# SN32F240B register map
Vendor: SONiX Technology Co., Ltd.; Series: SN32F240B; File version: 1.1
CPU: CM0 r0p0, little endian, no MPU, no FPU, 2 interrupt priority bits
Registers are 32-bit, read-write, reset 0x0 unless marked. A register's access mark holds for its fields unless they carry their own. Offsets are from the block's base; [hi:lo] are bit positions; {n}, {i} and the like mark numbered series.

## SN_SYS1 — System Control Registers
Base 0x4005E000
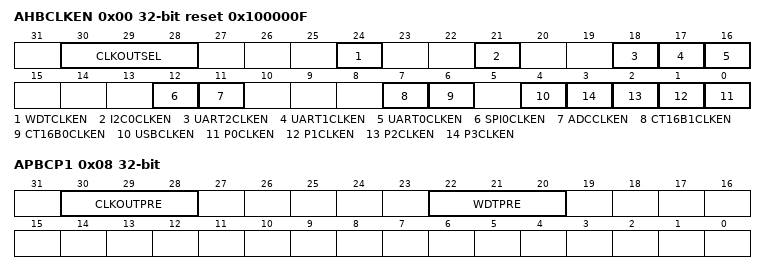
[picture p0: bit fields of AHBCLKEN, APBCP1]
0x00 AHBCLKEN reset 0x100000F — Offset:0x00 AHB Clock Enable Register
  [30:28] CLKOUTSEL — Clock output source selection
    0=Disable; 1=ILRC; 4=HCLK; 5=IHRC
  [24] WDTCLKEN — Enable AHB clock for WDT
    0=Disable; 1=Enable
  [21] I2C0CLKEN — Enable AHB clock for I2C0
    0=Disable; 1=Enable
  [18] UART2CLKEN — Enable AHB clock for UART2
    0=Disable; 1=Enable
  [17] UART1CLKEN — Enable AHB clock for UART1
    0=Disable; 1=Enable
  [16] UART0CLKEN — Enable AHB clock for UART0
    0=Disable; 1=Enable
  [12] SPI0CLKEN — Enable AHB clock for SPI0
    0=Disable; 1=Enable
  [11] ADCCLKEN — Enable AHB clock for ADC
    0=Disable; 1=Enable
  [7] CT16B1CLKEN — Enable AHB clock for CT16B1
    0=Disable; 1=Enable
  [6] CT16B0CLKEN — Enable AHB clock for CT16B0
    0=Disable; 1=Enable
  [4] USBCLKEN — Enable AHB clock for USB
    0=Disable; 1=Enable
  [n] P{n}CLKEN (n=0..3) — Enable AHB clock for P{n}
    0=Disable; 1=Enable
0x08 APBCP1 — Offset:0x08 APB Clock Prescale Register 1
  [30:28] CLKOUTPRE — CLKOUT APB clock source prescaler
    0=FCLKOUT/1; 1=FCLKOUT/2; 2=FCLKOUT/4; 3=FCLKOUT/8; 4=FCLKOUT/16; 5=FCLKOUT/32; 6=FCLKOUT/64; 7=FCLKOUT/128
  [22:20] WDTPRE — WDT APB clock source prescaler
    0=WDT_PCLK = WDT clock source/1; 1=WDT_PCLK = WDT clock source/2; 2=WDT_PCLK = WDT clock source/4; 3=WDT_PCLK = WDT clock source/8; 4=WDT_PCLK = WDT clock source/16; 5=WDT_PCLK = WDT clock source/32

## SN_PMU — Power Management Unit
Base 0x40032000
0x40 CTRL — Offset:0x40 PMU Control Register
  [2:0] MODE — Low Power mode selection
    0=Disable; 2=Deep-sleep mode (WFI instruction will make MCU enter Deep-sleep mode); 4=Sleep mode (WFI instruction will make MCU enter Sleep mode)

## SN_PFPA — Peripheral Function Pin Assignment
Base 0x40042000
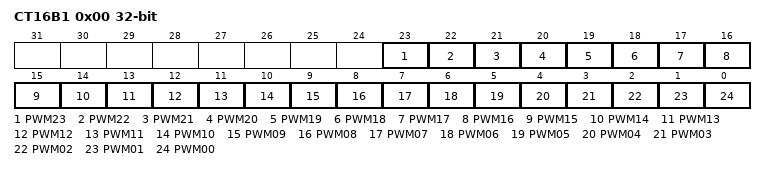
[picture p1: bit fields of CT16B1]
0x00 CT16B1 — Offset:0x00 PFPA for CT16B1 Register
  [23] PWM23 — CT16B1_PWM23 assigned pin
    0=P1.7 (CT16B1_PWM23=P1.7); 1=P2.15 (CT16B1_PWM23=P2.15)
  [22] PWM22 — CT16B1_PWM22 assigned pin
    0=P1.6 (CT16B1_PWM22=P1.6); 1=P2.14 (CT16B1_PWM22=P2.14)
  [21] PWM21 — CT16B1_PWM21 assigned pin
    0=P1.5 (CT16B1_PWM21=P1.5); 1=P2.13 (CT16B1_PWM21=P2.13)
  [20] PWM20 — CT16B1_PWM20 assigned pin
    0=P1.4 (CT16B1_PWM20=P1.4); 1=P2.12 (CT16B1_PWM20=P2.12)
  [19] PWM19 — CT16B1_PWM19 assigned pin
    0=P1.3 (CT16B1_PWM19=P1.3); 1=P2.11 (CT16B1_PWM19=P2.11)
  [18] PWM18 — CT16B1_PWM18 assigned pin
    0=P1.2 (CT16B1_PWM18=P1.2); 1=P2.10 (CT16B1_PWM18=P2.10)
  [17] PWM17 — CT16B1_PWM17 assigned pin
    0=P1.1 (CT16B1_PWM17=P1.1); 1=P2.9 (CT16B1_PWM17=P2.9)
  [16] PWM16 — CT16B1_PWM16 assigned pin
    0=P1.0 (CT16B1_PWM16=P1.0); 1=P2.8 (CT16B1_PWM16=P2.8)
  [15] PWM15 — CT16B1_PWM15 assigned pin
    0=P0.15 (CT16B1_PWM15=P0.15); 1=P2.7 (CT16B1_PWM15=P2.7)
  [14] PWM14 — CT16B1_PWM14 assigned pin
    0=P0.14 (CT16B1_PWM14=P0.14); 1=P2.6 (CT16B1_PWM14=P2.6)
  [13] PWM13 — CT16B1_PWM13 assigned pin
    0=P0.13 (CT16B1_PWM13=P0.13); 1=P2.5 (CT16B1_PWM13=P2.5)
  [12] PWM12 — CT16B1_PWM12 assigned pin
    0=P0.12 (CT16B1_PWM12=P0.12); 1=P2.4 (CT16B1_PWM12=P2.4)
  [11] PWM11 — CT16B1_PWM11 assigned pin
    0=P0.11 (CT16B1_PWM11=P0.11); 1=P2.3 (CT16B1_PWM11=P2.3)
  [10] PWM10 — CT16B1_PWM10 assigned pin
    0=P0.10 (CT16B1_PWM10=P0.10); 1=P2.2 (CT16B1_PWM10=P2.2)
  [9] PWM09 — CT16B1_PWM09 assigned pin
    0=P0.9 (CT16B1_PWM09=P0.9); 1=P2.1 (CT16B1_PWM09=P2.1)
  [8] PWM08 — CT16B1_PWM08 assigned pin
    0=P0.8 (CT16B1_PWM08=P0.8); 1=P2.0 (CT16B1_PWM08=P2.0)
  [7] PWM07 — CT16B1_PWM07 assigned pin
    0=P0.7 (CT16B1_PWM07=P0.7); 1=P1.15 (CT16B1_PWM07=P1.15)
  [6] PWM06 — CT16B1_PWM06 assigned pin
    0=P0.6 (CT16B1_PWM06=P0.6); 1=P1.14 (CT16B1_PWM06=P1.14)
  [5] PWM05 — CT16B1_PWM05 assigned pin
    0=P0.5 (CT16B1_PWM05=P0.5); 1=P1.13 (CT16B1_PWM05=P1.13)
  [4] PWM04 — CT16B1_PWM04 assigned pin
    0=P0.4 (CT16B1_PWM04=P0.4); 1=P1.12 (CT16B1_PWM04=P1.12)
  [3] PWM03 — CT16B1_PWM03 assigned pin
    0=P0.3 (CT16B1_PWM03=P0.3); 1=P1.11 (CT16B1_PWM03=P1.11)
  [2] PWM02 — CT16B1_PWM02 assigned pin
    0=P0.2 (CT16B1_PWM02=P0.2); 1=P1.10 (CT16B1_PWM02=P1.10)
  [1] PWM01 — CT16B1_PWM01 assigned pin
    0=P0.1 (CT16B1_PWM01=P0.1); 1=P1.9 (CT16B1_PWM01=P1.9)
  [0] PWM00 — CT16B1_PWM00 assigned pin
    0=P0.0 (CT16B1_PWM00=P0.0); 1=P1.8 (CT16B1_PWM00=P1.8)
